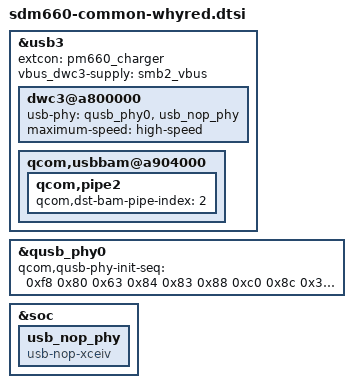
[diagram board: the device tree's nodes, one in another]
&usb3 {
	extcon = <&pm660_charger>;
	vbus_dwc3-supply = <&smb2_vbus>;

	dwc3@a800000 {
		usb-phy = <&qusb_phy0>, <&usb_nop_phy>;
		maximum-speed = "high-speed";
	};

	qcom,usbbam@a904000 {
		qcom,pipe2 {
			qcom,dst-bam-pipe-index = <2>;
		};
	};
};

&qusb_phy0 {
	qcom,qusb-phy-init-seq = <0xf8 0x80
				0x63 0x84
				0x83 0x88
				0xc0 0x8c
				0x30 0x08
				0x79 0x0c
				0x21 0x10
				0x14 0x9c
				0x9f 0x1c
				0x00 0x18>;
};

&soc {
	usb_nop_phy: usb_nop_phy {
		compatible = "usb-nop-xceiv";
	};
};
